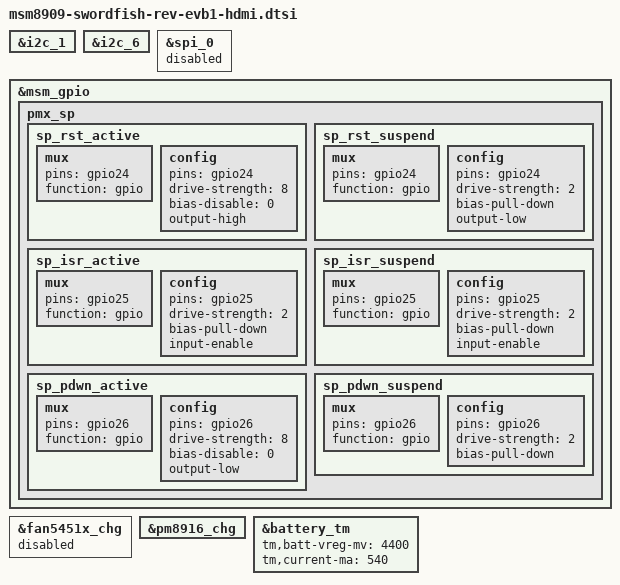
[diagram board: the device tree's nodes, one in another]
/* Copyright (c) 2016, LGE Inc. All rights reserved.
 *
 * This program is free software; you can redistribute it and/or modify
 * it under the terms of the GNU General Public License version 2 and
 * only version 2 as published by the Free Software Foundation.
 *
 * This program is distributed in the hope that it will be useful,
 * but WITHOUT ANY WARRANTY; without even the implied warranty of
 * MERCHANTABILITY or FITNESS FOR A PARTICULAR PURPOSE.  See the
 * GNU General Public License for more details.
 */

#include "msm8909-swordfish.dtsi"
#include "../qcom/msm8909w-gpu.dtsi"
#include "../qcom/msm8909-pm8916.dtsi"
#include "../qcom/msm8909w.dtsi"
#include "msm8909-swordfish-panel-hdmi.dtsi"
#include "msm8909-pm8916-swordfish.dtsi"
#include "msm8909-swordfish-sound.dtsi"
#include "msm8909-swordfish-hdmi.dtsi"

&i2c_1 {
	status = "okay";
};

&i2c_6 {
	status = "ok";
};

&spi_0 {
	status = "disabled";
};

/* pinctrl for slimport */
&msm_gpio {
	pmx_sp {
		sp_rst_active: sp_rst_active {
			mux {
				pins = "gpio24";
				function = "gpio";
			};

			config {
				pins = "gpio24";
				drive-strength = <8>; /* 8 mA */
				bias-disable = <0>; /* no pull */
				output-high;
			};
		};

		sp_rst_suspend: sp_rst_suspend {
			mux {
				pins = "gpio24";
				function = "gpio";
			};

			config {
				pins = "gpio24";
				drive-strength = <2>; /* 2 mA */
				bias-pull-down; /* pull down */
				output-low;
			};
		};

		sp_isr_active: sp_isr_active {
			mux {
				pins = "gpio25";
				function = "gpio";
			};

			config {
				pins = "gpio25";
				drive-strength = <2>; /* 2 mA */
				bias-pull-down; /* pull down */
				input-enable;
			};
		};

		sp_isr_suspend: sp_isr_suspend {
			mux {
				pins = "gpio25";
				function = "gpio";
			};

			config {
				pins = "gpio25";
				drive-strength = <2>; /* 2 mA */
				bias-pull-down; /* pull down */
				input-enable;
			};
		};
		sp_pdwn_active: sp_pdwn_active {
			mux {
				pins = "gpio26";
				function = "gpio";
			};

			config {
				pins = "gpio26";
				drive-strength = <8>; /* 8 mA */
				bias-disable = <0>; /* no pull */
				output-low;
			};
		};

		sp_pdwn_suspend: sp_pdwn_suspend {
			mux {
				pins = "gpio26";
				function = "gpio";
		};

			config {
				pins = "gpio26";
				drive-strength = <2>; /* 2 mA */
				bias-pull-down; /* pull down */
			};
		};
	};
};

&fan5451x_chg {
	status = "disabled";
};

&pm8916_chg {
	status = "ok";
};

&battery_tm {
	tm,batt-vreg-mv = <4400>;
	tm,current-ma = <540>;
	/delete-property/ tm,wlc-config-use;
};
